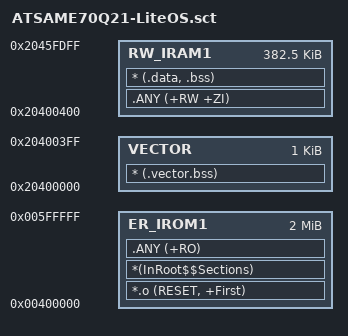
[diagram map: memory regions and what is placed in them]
; *************************************************************
; *** Scatter-Loading Description File generated by uVision ***
; *************************************************************

LR_IROM1 0x00400000 0x00200000  {    ; load region size_region
  ER_IROM1 0x00400000 0x00200000  {  ; load address = execution address
   *.o (RESET, +First)
   *(InRoot$$Sections)
   .ANY (+RO)
  }
  VECTOR 0x20400000 0x400 { ;vector
	* (.vector.bss)
  }

  RW_IRAM1 0x20400400 0x005fa00  {  ; RW data;RW_IRAM1 0x20010800 0x0003F800  {  ; RW data
   .ANY (+RW +ZI)
   * (.data, .bss)
  }
}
